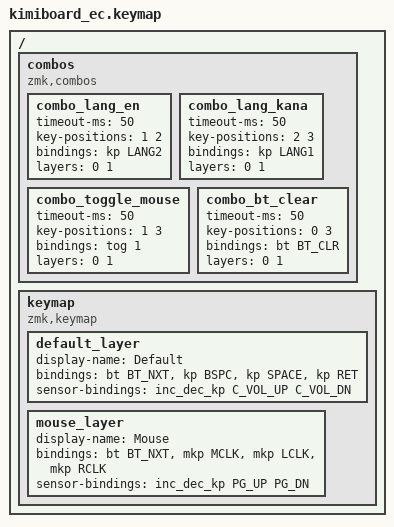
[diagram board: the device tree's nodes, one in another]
/*
 * KimiBoard EC キーマップ
 *
 * 物理配置 (kscan0のindexに対応):
 *   position 0: タクトスイッチ (旧「0キー」)
 *   position 1: キー1
 *   position 2: キー2
 *   position 3: キー3
 *   sensor(0)  : ロータリーエンコーダー (新規追加)
 *
 * 元のKimiBoardのコンビネーション操作(1+2, 2+3, 1+3, 0+3)を
 * ZMKのcombo機能で再現しています。
 */

#include <behaviors.dtsi>
#include <dt-bindings/zmk/keys.h>
#include <dt-bindings/zmk/bt.h>
#include <dt-bindings/zmk/mouse.h>
#include <dt-bindings/zmk/outputs.h>

/ {
    combos {
        compatible = "zmk,combos";

        combo_lang_en {
            timeout-ms = <50>;
            key-positions = <1 2>;   // キー1+キー2 : 英数入力
            bindings = <&kp LANG2>;
            layers = <0 1>;
        };

        combo_lang_kana {
            timeout-ms = <50>;
            key-positions = <2 3>;   // キー2+キー3 : かな入力
            bindings = <&kp LANG1>;
            layers = <0 1>;
        };

        combo_toggle_mouse {
            timeout-ms = <50>;
            key-positions = <1 3>;   // キー1+キー3 : 通常/マウスレイヤー切替
            bindings = <&tog 1>;
            layers = <0 1>;
        };

        combo_bt_clear {
            timeout-ms = <50>;
            key-positions = <0 3>;   // タクト+キー3 : 現在のBT接続先情報を削除
            bindings = <&bt BT_CLR>;
            layers = <0 1>;
        };
    };

    keymap {
        compatible = "zmk,keymap";

        // ---------------------------------------------
        // レイヤー0: 通常キーマップ
        // ---------------------------------------------
        default_layer {
            display-name = "Default";
            bindings = <
                &bt BT_NXT     &kp BSPC   &kp SPACE   &kp RET
            >;

            // エンコーダー: 音量アップ/ダウン(用途に応じて &kp C_VOL_UP/DN 以外にも変更可)
            sensor-bindings = <&inc_dec_kp C_VOL_UP C_VOL_DN>;
        };

        // ---------------------------------------------
        // レイヤー1: マウスボタンモード
        // ---------------------------------------------
        mouse_layer {
            display-name = "Mouse";
            bindings = <
                &bt BT_NXT     &mkp MCLK   &mkp LCLK   &mkp RCLK
            >;

            // マウスレイヤー中のエンコーダー: スクロール
            sensor-bindings = <&inc_dec_kp PG_UP PG_DN>;
        };
    };
};
